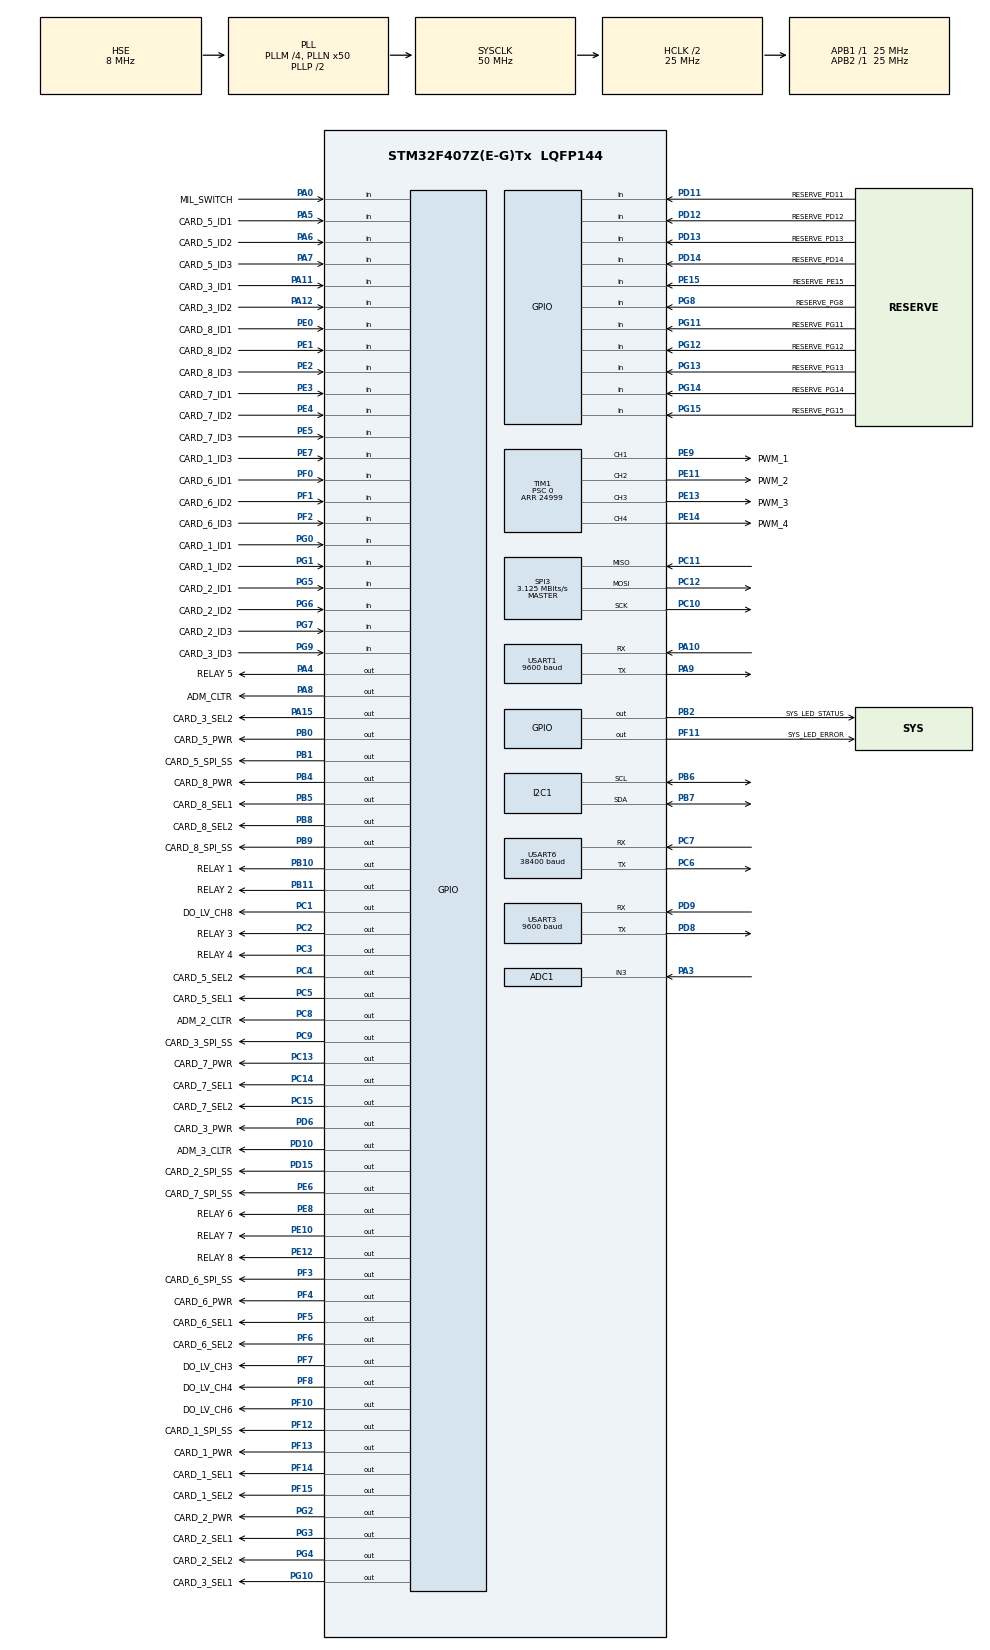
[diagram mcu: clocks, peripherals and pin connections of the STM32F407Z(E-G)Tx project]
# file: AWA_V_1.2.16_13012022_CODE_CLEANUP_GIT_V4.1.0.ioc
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ADC1.Channel-3\#ChannelRegularConversion=ADC_CHANNEL_3
ADC1.ContinuousConvMode=ENABLE
ADC1.EOCSelection=ADC_EOC_SEQ_CONV
ADC1.NbrOfConversion=1
ADC1.NbrOfConversionFlag=1
ADC1.Rank-3\#ChannelRegularConversion=1
ADC1.SamplingTime-3\#ChannelRegularConversion=ADC_SAMPLETIME_480CYCLES
ADC1.master=1
Dma.Request0=USART6_TX
Dma.USART6_TX.0.Direction=DMA_MEMORY_TO_PERIPH
Dma.USART6_TX.0.FIFOMode=DMA_FIFOMODE_DISABLE
Dma.USART6_TX.0.Instance=DMA2_Stream6
Dma.USART6_TX.0.MemDataAlignment=DMA_MDATAALIGN_BYTE
Dma.USART6_TX.0.MemInc=DMA_MINC_ENABLE
Dma.USART6_TX.0.Mode=DMA_NORMAL
Dma.USART6_TX.0.PeriphDataAlignment=DMA_PDATAALIGN_BYTE
Dma.USART6_TX.0.PeriphInc=DMA_PINC_DISABLE
Dma.USART6_TX.0.Priority=DMA_PRIORITY_VERY_HIGH
I2C1.I2C_Mode=I2C_Fast
Mcu.Family=STM32F4
Mcu.Name=STM32F407Z(E-G)Tx
Mcu.Package=LQFP144
NVIC.DMA2_Stream6_IRQn=true\:0\:0\:false\:false\:true\:true\:true
NVIC.PriorityGroup=NVIC_PRIORITYGROUP_4
NVIC.TIM2_IRQn=true\:0\:0\:false\:false\:true\:true\:true
NVIC.TIM3_IRQn=true\:0\:0\:true\:false\:true\:true\:true
NVIC.TIM4_IRQn=true\:0\:0\:false\:false\:true\:true\:true
NVIC.TIM5_IRQn=true\:0\:0\:false\:false\:true\:true\:true
NVIC.TIM6_DAC_IRQn=true\:0\:0\:false\:false\:true\:true\:true
NVIC.TIM7_IRQn=true\:0\:0\:false\:false\:true\:true\:true
NVIC.TIM8_BRK_TIM12_IRQn=true\:0\:0\:false\:false\:true\:true\:true
NVIC.USART1_IRQn=true\:0\:0\:false\:false\:true\:true\:true
NVIC.USART3_IRQn=true\:0\:0\:false\:false\:true\:true\:true
NVIC.USART6_IRQn=true\:0\:0\:false\:false\:true\:true\:true
PA0-WKUP.GPIO_Label=MIL_SWITCH
PA0-WKUP.Signal=GPIO_Input
PA10.Mode=Asynchronous
PA10.Signal=USART1_RX
PA11.GPIO_Label=CARD_3_ID1
PA11.Signal=GPIO_Input
PA12.GPIO_Label=CARD_3_ID2
PA12.Signal=GPIO_Input
PA13.Mode=Trace_Asynchronous_SW
PA13.Signal=SYS_JTMS-SWDIO
PA14.Mode=Trace_Asynchronous_SW
PA14.Signal=SYS_JTCK-SWCLK
PA15.GPIO_Label=CARD_3_SEL2
PA15.Signal=GPIO_Output
PA3.Signal=ADCx_IN3
PA4.GPIO_Label=RELAY 5
PA4.Signal=GPIO_Output
PA5.GPIO_Label=CARD_5_ID1
PA5.Signal=GPIO_Input
PA6.GPIO_Label=CARD_5_ID2
PA6.Signal=GPIO_Input
PA7.GPIO_Label=CARD_5_ID3
PA7.Signal=GPIO_Input
PA8.GPIO_Label=ADM_CLTR
PA8.Signal=GPIO_Output
PA9.Mode=Asynchronous
PA9.Signal=USART1_TX
PB0.GPIO_Label=CARD_5_PWR
PB0.Signal=GPIO_Output
PB1.GPIO_Label=CARD_5_SPI_SS
PB1.Signal=GPIO_Output
PB10.GPIO_Label=RELAY 1
PB10.Signal=GPIO_Output
PB11.GPIO_Label=RELAY 2
PB11.Signal=GPIO_Output
PB2.GPIO_Label=SYS_LED_STATUS
PB2.Signal=GPIO_Output
PB3.Mode=Trace_Asynchronous_SW
PB3.Signal=SYS_JTDO-SWO
PB4.GPIO_Label=CARD_8_PWR
PB4.Signal=GPIO_Output
PB5.GPIO_Label=CARD_8_SEL1
PB5.Signal=GPIO_Output
PB6.GPIO_PuPdOD=GPIO_NOPULL
PB6.Mode=I2C
PB6.Signal=I2C1_SCL
PB7.GPIO_PuPdOD=GPIO_NOPULL
PB7.Mode=I2C
PB7.Signal=I2C1_SDA
PB8.GPIO_Label=CARD_8_SEL2
PB8.Signal=GPIO_Output
PB9.GPIO_Label=CARD_8_SPI_SS
PB9.Signal=GPIO_Output
PC1.GPIO_Label=DO_LV_CH8
PC1.Signal=GPIO_Output
PC10.Mode=Full_Duplex_Master
PC10.Signal=SPI3_SCK
PC11.Mode=Full_Duplex_Master
PC11.Signal=SPI3_MISO
PC12.Mode=Full_Duplex_Master
PC12.Signal=SPI3_MOSI
PC13-ANTI_TAMP.GPIO_Label=CARD_7_PWR
PC13-ANTI_TAMP.Signal=GPIO_Output
PC14-OSC32_IN.GPIO_Label=CARD_7_SEL1
PC14-OSC32_IN.Signal=GPIO_Output
PC15-OSC32_OUT.GPIO_Label=CARD_7_SEL2
PC15-OSC32_OUT.Signal=GPIO_Output
PC2.GPIO_Label=RELAY 3
PC2.Signal=GPIO_Output
PC3.GPIO_Label=RELAY 4
PC3.Signal=GPIO_Output
PC4.GPIO_Label=CARD_5_SEL2
PC4.Signal=GPIO_Output
PC5.GPIO_Label=CARD_5_SEL1
PC5.Signal=GPIO_Output
PC6.Mode=Asynchronous
PC6.Signal=USART6_TX
PC7.Mode=Asynchronous
PC7.Signal=USART6_RX
PC8.GPIO_Label=ADM_2_CLTR
PC8.Signal=GPIO_Output
PC9.GPIO_Label=CARD_3_SPI_SS
PC9.Signal=GPIO_Output
PD10.GPIO_Label=ADM_3_CLTR
PD10.Signal=GPIO_Output
PD11.GPIO_Label=RESERVE_PD11
PD11.Signal=GPIO_Input
PD12.GPIO_Label=RESERVE_PD12
PD12.Signal=GPIO_Input
PD13.GPIO_Label=RESERVE_PD13
PD13.Signal=GPIO_Input
PD14.GPIO_Label=RESERVE_PD14
PD14.Signal=GPIO_Input
PD15.GPIO_Label=CARD_2_SPI_SS
PD15.Signal=GPIO_Output
PD6.GPIO_Label=CARD_3_PWR
PD6.Signal=GPIO_Output
PD8.Mode=Asynchronous
PD8.Signal=USART3_TX
PD9.Mode=Asynchronous
PD9.Signal=USART3_RX
PE0.GPIO_Label=CARD_8_ID1
PE0.Signal=GPIO_Input
PE1.GPIO_Label=CARD_8_ID2
PE1.Signal=GPIO_Input
PE10.GPIO_Label=RELAY 7
PE10.Signal=GPIO_Output
PE11.GPIO_Label=PWM_2
PE11.Signal=S_TIM1_CH2
PE12.GPIO_Label=RELAY 8
PE12.Signal=GPIO_Output
PE13.GPIO_Label=PWM_3
PE13.Signal=S_TIM1_CH3
PE14.GPIO_Label=PWM_4
PE14.Signal=S_TIM1_CH4
PE15.GPIO_Label=RESERVE_PE15
PE15.Signal=GPIO_Input
PE2.GPIO_Label=CARD_8_ID3
PE2.Signal=GPIO_Input
PE3.GPIO_Label=CARD_7_ID1
PE3.Signal=GPIO_Input
PE4.GPIO_Label=CARD_7_ID2
PE4.Signal=GPIO_Input
PE5.GPIO_Label=CARD_7_ID3
PE5.Signal=GPIO_Input
PE6.GPIO_Label=CARD_7_SPI_SS
PE6.Signal=GPIO_Output
PE7.GPIO_Label=CARD_1_ID3
PE7.Signal=GPIO_Input
PE8.GPIO_Label=RELAY 6
PE8.Signal=GPIO_Output
PE9.GPIO_Label=PWM_1
PE9.Signal=S_TIM1_CH1
PF0.GPIO_Label=CARD_6_ID1
PF0.Signal=GPIO_Input
PF1.GPIO_Label=CARD_6_ID2
PF1.Signal=GPIO_Input
PF10.GPIO_Label=DO_LV_CH6
PF10.Signal=GPIO_Output
PF11.GPIO_Label=SYS_LED_ERROR
PF11.Signal=GPIO_Output
PF12.GPIO_Label=CARD_1_SPI_SS
PF12.Signal=GPIO_Output
PF13.GPIO_Label=CARD_1_PWR
PF13.Signal=GPIO_Output
PF14.GPIO_Label=CARD_1_SEL1
PF14.Signal=GPIO_Output
PF15.GPIO_Label=CARD_1_SEL2
PF15.Signal=GPIO_Output
PF2.GPIO_Label=CARD_6_ID3
PF2.Signal=GPIO_Input
PF3.GPIO_Label=CARD_6_SPI_SS
PF3.Signal=GPIO_Output
PF4.GPIO_Label=CARD_6_PWR
PF4.Signal=GPIO_Output
PF5.GPIO_Label=CARD_6_SEL1
PF5.Signal=GPIO_Output
PF6.GPIO_Label=CARD_6_SEL2
PF6.Signal=GPIO_Output
PF7.GPIO_Label=DO_LV_CH3
PF7.Signal=GPIO_Output
PF8.GPIO_Label=DO_LV_CH4
PF8.Signal=GPIO_Output
PG0.GPIO_Label=CARD_1_ID1
PG0.Signal=GPIO_Input
PG1.GPIO_Label=CARD_1_ID2
PG1.Signal=GPIO_Input
PG10.GPIO_Label=CARD_3_SEL1
PG10.Signal=GPIO_Output
PG11.GPIO_Label=RESERVE_PG11
PG11.Signal=GPIO_Input
PG12.GPIO_Label=RESERVE_PG12
PG12.Signal=GPIO_Input
PG13.GPIO_Label=RESERVE_PG13
PG13.Signal=GPIO_Input
PG14.GPIO_Label=RESERVE_PG14
PG14.Signal=GPIO_Input
PG15.GPIO_Label=RESERVE_PG15
PG15.Signal=GPIO_Input
PG2.GPIO_Label=CARD_2_PWR
PG2.Signal=GPIO_Output
PG3.GPIO_Label=CARD_2_SEL1
PG3.Signal=GPIO_Output
PG4.GPIO_Label=CARD_2_SEL2
PG4.Signal=GPIO_Output
PG5.GPIO_Label=CARD_2_ID1
PG5.Signal=GPIO_Input
PG6.GPIO_Label=CARD_2_ID2
PG6.Signal=GPIO_Input
PG7.GPIO_Label=CARD_2_ID3
PG7.Signal=GPIO_Input
PG8.GPIO_Label=RESERVE_PG8
PG8.Signal=GPIO_Input
PG9.GPIO_Label=CARD_3_ID3
PG9.Signal=GPIO_Input
PH0-OSC_IN.Mode=HSE-External-Oscillator
PH0-OSC_IN.Signal=RCC_OSC_IN
PH1-OSC_OUT.Mode=HSE-External-Oscillator
PH1-OSC_OUT.Signal=RCC_OSC_OUT
ProjectManager.HeapSize=0x200
ProjectManager.StackSize=0x400
ProjectManager.TargetToolchain=STM32CubeIDE
RCC.48MHZClocksFreq_Value=25000000
RCC.AHBCLKDivider=RCC_SYSCLK_DIV2
RCC.AHBFreq_Value=25000000
RCC.APB1Freq_Value=25000000
RCC.APB1TimFreq_Value=25000000
RCC.APB2Freq_Value=25000000
RCC.APB2TimFreq_Value=25000000
RCC.CortexFreq_Value=25000000
RCC.HCLKFreq_Value=25000000
RCC.HSE_VALUE=8000000
RCC.HSI_VALUE=16000000
RCC.LSE_VALUE=32768
RCC.PLLM=4
RCC.PLLN=50
RCC.PLLSourceVirtual=RCC_PLLSOURCE_HSE
RCC.SYSCLKFreq_VALUE=50000000
RCC.SYSCLKSource=RCC_SYSCLKSOURCE_PLLCLK
RCC.VCOOutputFreq_Value=100000000
SH.ADCx_IN3.0=ADC1_IN3,IN3
SH.S_TIM1_CH1.0=TIM1_CH1,PWM Generation1 CH1
SH.S_TIM1_CH2.0=TIM1_CH2,PWM Generation2 CH2
SH.S_TIM1_CH3.0=TIM1_CH3,PWM Generation3 CH3
SH.S_TIM1_CH4.0=TIM1_CH4,PWM Generation4 CH4
SPI3.BaudRatePrescaler=SPI_BAUDRATEPRESCALER_8
SPI3.CalculateBaudRate=3.125 MBits/s
SPI3.DataSize=SPI_DATASIZE_16BIT
SPI3.Direction=SPI_DIRECTION_2LINES
SPI3.Mode=SPI_MODE_MASTER
SPI3.VirtualType=VM_MASTER
TIM1.AutoReloadPreload=TIM_AUTORELOAD_PRELOAD_DISABLE
TIM1.Channel-PWM\ Generation1\ CH1=TIM_CHANNEL_1
TIM1.Channel-PWM\ Generation2\ CH2=TIM_CHANNEL_2
TIM1.Channel-PWM\ Generation3\ CH3=TIM_CHANNEL_3
TIM1.Channel-PWM\ Generation4\ CH4=TIM_CHANNEL_4
TIM1.OCMode_PWM-PWM\ Generation1\ CH1=TIM_OCMODE_PWM2
TIM1.Period=24999
TIM1.Prescaler=0
TIM1.Pulse-PWM\ Generation1\ CH1=4000
TIM1.Pulse-PWM\ Generation2\ CH2=32
TIM1.Pulse-PWM\ Generation3\ CH3=32
TIM1.Pulse-PWM\ Generation4\ CH4=32
TIM12.Period=1
TIM12.Prescaler=2499
TIM2.AutoReloadPreload=TIM_AUTORELOAD_PRELOAD_ENABLE
TIM2.Period=99
TIM2.Prescaler=24
TIM3.Period=8
TIM3.Prescaler=24999
TIM4.Period=800
TIM4.Prescaler=25
TIM5.Period=1
TIM5.Prescaler=2499
TIM6.Period=999
TIM6.Prescaler=24999
TIM7.Period=1
TIM7.Prescaler=2499
USART1.BaudRate=9600
USART1.Parity=PARITY_NONE
USART1.StopBits=STOPBITS_1
USART1.VirtualMode=VM_ASYNC
USART3.BaudRate=9600
USART3.Parity=PARITY_NONE
USART3.VirtualMode=VM_ASYNC
USART6.BaudRate=38400
USART6.OverSampling=UART_OVERSAMPLING_8
USART6.Parity=PARITY_NONE
USART6.StopBits=STOPBITS_1
USART6.VirtualMode=VM_ASYNC
USART6.WordLength=WORDLENGTH_8B
VP_TIM12_VS_ClockSourceINT.Mode=Internal
VP_TIM1_VS_ClockSourceINT.Mode=Internal
VP_TIM2_VS_ClockSourceINT.Mode=Internal
VP_TIM3_VS_ClockSourceINT.Mode=Internal
VP_TIM4_VS_ClockSourceINT.Mode=Internal
VP_TIM5_VS_ClockSourceINT.Mode=Internal
VP_TIM6_VS_ClockSourceINT.Mode=Enable_Timer
VP_TIM7_VS_ClockSourceINT.Mode=Enable_Timer
board=custom

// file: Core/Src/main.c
/* USER CODE BEGIN Header */
/**
  ******************************************************************************
  * @file           : main.c
  * @brief          : Main program body
  ******************************************************************************
  * @attention
  *
  * <h2><center>&copy; Copyright (c) 2021 STMicroelectronics.
  * All rights reserved.</center></h2>
  *
  * This software component is licensed by ST under BSD 3-Clause license,
  * the "License"; You may not use this file except in compliance with the
  * License. You may obtain a copy of the License at:
  *                        opensource.org/licenses/BSD-3-Clause
  *
  ******************************************************************************
  */
/* USER CODE END Header */

#include "main.h"

/* USER CODE BEGIN Includes */
#include<stdlib.h>
#include<string.h>
#include "FM24CL64B.h"
#include "ADS1115.h"
#include "AD7682.h"
#include <math.h>
#include "stm32f4xx_dma.h"
#include "Application.h"
#include "Calibration.h"
#include "Initialization.h"
#include <time.h>

#define ITM_Port32(n)	(*((volatile unsigned long *)(0xe0000000 +4*n)))
#define SINGLE_SHOT 0
#define TEST	0
/* USER CODE END Includes */

ADC_HandleTypeDef hadc1;

I2C_HandleTypeDef hi2c1;

SPI_HandleTypeDef hspi3;

TIM_HandleTypeDef htim1;
TIM_HandleTypeDef htim2;
TIM_HandleTypeDef htim3;
TIM_HandleTypeDef htim4;
TIM_HandleTypeDef htim5;
TIM_HandleTypeDef htim6;
TIM_HandleTypeDef htim7;
TIM_HandleTypeDef htim12;

UART_HandleTypeDef huart1;
UART_HandleTypeDef huart3;
UART_HandleTypeDef huart6;
DMA_HandleTypeDef hdma_usart6_tx;

/* USER CODE BEGIN PV */
extern uint8_t uart_rx_buffer;			/*< Will receive single byte from UART and will transfer it to the RX buffer array.*/
extern uint8_t uart_rx_buffer_uart1;	/*< Will receive single byte from UART and will transfer it to the RX buffer array.*/
extern uint8_t uart_rx_buffer_uart3;	/*< Will receive single byte from UART and will transfer it to the RX buffer array.*/
/* USER CODE END PV */

void SystemClock_Config(void);
static void MX_GPIO_Init(void);
static void MX_TIM2_Init(void);
static void MX_TIM3_Init(void);
static void MX_TIM4_Init(void);
static void MX_I2C1_Init(void);
static void MX_SPI3_Init(void);
static void MX_TIM1_Init(void);
static void MX_USART3_UART_Init(void);
static void MX_TIM6_Init(void);
static void MX_USART1_UART_Init(void);
static void MX_USART6_UART_Init(void);
static void MX_ADC1_Init(void);
static void MX_DMA_Init(void);
static void MX_TIM7_Init(void);
static void MX_TIM5_Init(void);
static void MX_TIM12_Init(void);
/* USER CODE BEGIN PFP */

void ProcessCommandCommands(void);

void PWM_update(void);//test

float LinearEqCalc(float x, float x1, float x2, float y1, float y2);

/* USER CODE END PFP */

/* USER CODE BEGIN 0 */
uint8_t p[10];

uint16_t SlotCode[8];

int card_action = 0;
int calFlag = 0;

uint8_t cardScan = 1;
extern ADS1115_Config ADS1115_ReadConfigutationHandle_t;
typedef union{
	uint8_t bytes[2];
	uint16_t word;
}Data;
Data data_;

//AutoZero flag
uint8_t performAUTOZERO;
//Batch mode
uint8_t performBatchCycle;

int _write(int file, char *ptr, int len)
{
	int DataIdx;

	for (DataIdx = 0; DataIdx < len; DataIdx++)
	{
		//__io_putchar(*ptr++);
		ITM_SendChar(*ptr++);
	}
	return len;
}

static inline getconfig(void)
{
	data_.word = ADS1115_OperationReadConfiguration();
	ADS1115_ReadConfigutationHandle_t.ByteData[1] = data_.bytes[0];
	ADS1115_ReadConfigutationHandle_t.ByteData[0] = data_.bytes[1];
}
/* USER CODE END 0 */

int main(void)
{
  /* USER CODE BEGIN 1 */
  //Delay for other peripherals to initialise
//  HAL_Delay(20);
  //unsigned char SlotNo = 0;

  /* USER CODE END 1 */

  /* MCU Configuration--------------------------------------------------------*/

  /* Reset of all peripherals, Initializes the Flash interface and the Systick. */
  HAL_Init();

  /* Configure the system clock */
  SystemClock_Config();

  /* USER CODE BEGIN SysInit */
  ITM_Port32(31) = 1;
#if MODBUS_MULTI_DROP
  //HAL_UART_Receive_IT(&huart6, &uart_rx_buffer, 1);
#else
  //Configure DMA for UART 6 RX
  DMA_UART6_RX_Init();
#endif

  //Configure DMA for UART 1 RX
  //DMA_UART1_RX_Init();
#if QUERRY_RX_INIT_LEN_6
  DMA_UART1_RX_Init((uint32_t*)(&Rxbuff[0]),DMA_FIRST_TRANSACTION_NO); /*< Initialize the DMA2 Stream 5 with DMA_FIRST_TRANSACTION_NO*/
#else
  //DMA_UART1_RX_Init((uint32_t*)(&Rxbuff[0]),8); /*< Initialize the DMA2 Stream 5 with DMA_FIRST_TRANSACTION_NO*/
#endif
  /* USER CODE END SysInit */

  /* Initialize all configured peripherals */
  MX_GPIO_Init();
  MX_TIM2_Init();
  MX_TIM3_Init();
  MX_TIM4_Init();
  MX_I2C1_Init();
  MX_SPI3_Init();
  MX_TIM1_Init();
  MX_USART3_UART_Init();
  MX_TIM6_Init();
  MX_USART1_UART_Init();
  MX_USART6_UART_Init();
  MX_ADC1_Init();
  MX_DMA_Init();
  MX_TIM7_Init();
  MX_TIM5_Init();
  MX_TIM12_Init();
  /* USER CODE BEGIN 2 */
  ITM_Port32(31) = 2;

  //Enable the DMA 2 Stream for UART 6 RX
  //DMAPeripheralEnable(DMA2_Stream2, ENABLE);

  //Start the reception in UART6 using interrupt
  HAL_UART_Receive_IT(&huart6, &uart_rx_buffer, 1);

  //Enable the DMA 2 Stream for UART 1 RX
  //DMAPeripheralEnable(DMA2_Stream5, ENABLE);

  //Start the reception in UART6 using interrupt
  HAL_UART_Receive_IT(&huart1, &uart_rx_buffer_uart1, 1);

  //Start UART3 on interrupt
  HAL_UART_Receive_IT(&huart3, &uart_rx_buffer_uart3, 1);
  /* USER CODE END 2 */

  /* Infinite loop */
  /* USER CODE BEGIN WHILE */
  ADM_CLTR_LOW();

  ADM_2_CLTR_LOW();

  ADM_3_CLTR_LOW();
  //test
//  HoldingRegisterdefaultData();
  //FRAM_OperationWrite(FRAM_ADDRESS_CODSENSORLASTCALIB_HISTORY,(uint8_t*)&InputRegister_t.bytes[sizeof(PVhandle_t) + 328],204);
  //FRAM_OperationWrite(FRAM_ADDRESS_TSSSENSORLASTCALIB_HISTORY,(uint8_t*)&InputRegister_t.bytes[sizeof(PVhandle_t) + 532],204);
  //FRAM_OperationWrite(FRAM_ADDRESS_PHSENSLASTCALIB_HISTORY,(uint8_t*)&InputRegister_t.bytes[sizeof(PVhandle_t) + 532],204);
  //FRAM_OperationWrite(FRAM_ADDRESS_MIN,'\0',(1024*8)-1);
  ModbusReadConfiguration();
  HoldingRegisterdefaultData();
  startupMessages();
  /**************************/

  PWM_setup();
  HAL_TIM_PWM_Start(&htim1, TIM_CHANNEL_1);
  HAL_TIM_PWM_Start(&htim1, TIM_CHANNEL_2);
  HAL_TIM_PWM_Start(&htim1, TIM_CHANNEL_3);
  HAL_TIM_PWM_Start(&htim1, TIM_CHANNEL_4);

  HAL_GPIO_WritePin(SYS_LED_STATUS_GPIO_Port, SYS_LED_STATUS_Pin, GPIO_PIN_SET);
  HAL_GPIO_WritePin(SYS_LED_ERROR_GPIO_Port, SYS_LED_ERROR_Pin, GPIO_PIN_SET);

  //Read the ID in every SLOT
  ReadSlotID();

  //this is set to 0x01 when the start ADC command is received
  TimerStart = 0x02;
  //printf("Hello AWA!!!\n");
  //memset(&InputRegister_t.bytes[sizeof(PVhandle_t)],'\0',sizeof(InputRegister_t.bytes));
//  int flag_= 0;
  //FRAM_OperationWrite(FRAM_ADDRESS_LASTCALIB_HISTORY,(uint8_t*)&InputRegister_t.bytes[sizeof(PVhandle_t)],sizeof(InputRegister_t.bytes));
  //int size = sizeof(PVhandle_t) + sizeof(InputRegister_t.COD_lastCalibration);
#if TEST
  memset(&CurrentOutputCalibration_t,'\0',sizeof(CurrentOutputCalibration_t));
  FRAM_OperationWrite(FRAM_ADDRESS_AO_ELEC_CALIB, (uint8_t*)&CurrentOutputCalibration_t, sizeof(CurrentOutputCalibration_t));
#endif
  //float arrayADC [1000];
  uint16_t samples = 100;
  //float avgs = (float)samples;

  /*Start the internal ADC*/
  InternalADCStartConversion();

  //Initiate the queue
  initqueue();

  float Current_COD_SF = 0;
  float Current_TSS_SF = 0;
  float Current_COD_C[4];
  float Current_TSS_C[3];
  float Current_CheckScreen_sample_on_time = 0;
  float Current_CheckScreen_sample_wait_time = 0;
  float Current_CheckScreen_clean_on_time = 0;
  float Current_CheckScreen_clean_wait_time = 0;
  float Current_CheckScreen_No_of_flashes = 0;

  Current_COD_SF = HoldingRegister_t.ModeCommand_t.COD_SF;
  Current_TSS_SF = HoldingRegister_t.ModeCommand_t.TSS_SF;
  //memcpy(HoldingRegister_t.ModeCommand_t.C,Current_COD_C,sizeof(Current_COD_C));//Source,dest,size
  //memcpy(HoldingRegister_t.ModeCommand_t.TSS_K,Current_TSS_C,sizeof(Current_TSS_C));
  Current_CheckScreen_sample_on_time = HoldingRegister_t.ModeCommand_t.CS_PUMP1_ONTIME;
  Current_CheckScreen_sample_wait_time = HoldingRegister_t.ModeCommand_t.CS_PUMP1_DELAY;
  Current_CheckScreen_clean_on_time = HoldingRegister_t.ModeCommand_t.CS_PUMP2_ONTIME;
  Current_CheckScreen_clean_wait_time = HoldingRegister_t.ModeCommand_t.CS_PUMP2_DELAY;
  Current_CheckScreen_No_of_flashes = HoldingRegister_t.ModeCommand_t.CS_FLASH;

  while (1)
  {

	  //Process the commands from the HMI
	  ProcessModesCommands();

	  //Relay outputs and analog outputs
	  Application_AWAIOProcess();

    /* USER CODE END WHILE */

    /* USER CODE BEGIN 3 */

	  //Parses the data received from the MODBUS master and execute the command received
	  Application_MODBUSParseQuery();

	  //Stores the process variables and calibration data if the respective flag is raised
	  Application_StoreData();

	  /*COD process controls*/
	  FlowSensorReadStatus();
	  MILSwitchReadStatus();

	  //Send the data to RTU
	  setRTUData();

	  //Check for data change
	  if(Current_COD_SF != HoldingRegister_t.ModeCommand_t.COD_SF ||
			Current_TSS_SF != HoldingRegister_t.ModeCommand_t.TSS_SF ||
			Current_CheckScreen_sample_on_time != HoldingRegister_t.ModeCommand_t.CS_PUMP1_ONTIME||
			Current_CheckScreen_sample_wait_time != HoldingRegister_t.ModeCommand_t.CS_PUMP1_DELAY||
			Current_CheckScreen_clean_on_time != HoldingRegister_t.ModeCommand_t.CS_PUMP2_ONTIME||
			Current_CheckScreen_clean_wait_time != HoldingRegister_t.ModeCommand_t.CS_PUMP2_DELAY||
			Current_CheckScreen_No_of_flashes != HoldingRegister_t.ModeCommand_t.CS_FLASH)
	  {
		  Current_COD_SF = HoldingRegister_t.ModeCommand_t.COD_SF;
		  COD_10ptFactoryCalibrationHandle_t.SF = Current_COD_SF;

		  Current_TSS_SF = HoldingRegister_t.ModeCommand_t.TSS_SF;
		  TSS_10ptFactoryCalibrationHandle_t.SF = Current_TSS_SF;

		  Current_CheckScreen_sample_on_time = HoldingRegister_t.ModeCommand_t.CS_PUMP1_ONTIME;
		  Current_CheckScreen_sample_wait_time = HoldingRegister_t.ModeCommand_t.CS_PUMP1_DELAY;
		  Current_CheckScreen_clean_on_time = HoldingRegister_t.ModeCommand_t.CS_PUMP2_ONTIME;
		  Current_CheckScreen_clean_wait_time = HoldingRegister_t.ModeCommand_t.CS_PUMP2_DELAY;

		  Current_CheckScreen_No_of_flashes = HoldingRegister_t.ModeCommand_t.CS_FLASH;

		  FRAM_OperationWrite(FRAM_ADDRESS_MIN, (uint8_t*)&HoldingRegister_t.bytes, sizeof(HoldingRegister_t.bytes));
	  }
  }
  /* USER CODE END 3 */
}

void SystemClock_Config(void)
{
  RCC_OscInitTypeDef RCC_OscInitStruct = {0};
  RCC_ClkInitTypeDef RCC_ClkInitStruct = {0};

  /** Configure the main internal regulator output voltage
  */
  __HAL_RCC_PWR_CLK_ENABLE();
  __HAL_PWR_VOLTAGESCALING_CONFIG(PWR_REGULATOR_VOLTAGE_SCALE1);
  /** Initializes the CPU, AHB and APB busses clocks
  */
  RCC_OscInitStruct.OscillatorType = RCC_OSCILLATORTYPE_HSE;
  RCC_OscInitStruct.HSEState = RCC_HSE_ON;
  RCC_OscInitStruct.PLL.PLLState = RCC_PLL_ON;
  RCC_OscInitStruct.PLL.PLLSource = RCC_PLLSOURCE_HSE;
  RCC_OscInitStruct.PLL.PLLM = 4;
  RCC_OscInitStruct.PLL.PLLN = 50;
  RCC_OscInitStruct.PLL.PLLP = RCC_PLLP_DIV2;
  RCC_OscInitStruct.PLL.PLLQ = 4;
  if (HAL_RCC_OscConfig(&RCC_OscInitStruct) != HAL_OK)
  {
    Error_Handler();
  }
  /** Initializes the CPU, AHB and APB busses clocks
  */
  RCC_ClkInitStruct.ClockType = RCC_CLOCKTYPE_HCLK|RCC_CLOCKTYPE_SYSCLK
                              |RCC_CLOCKTYPE_PCLK1|RCC_CLOCKTYPE_PCLK2;
  RCC_ClkInitStruct.SYSCLKSource = RCC_SYSCLKSOURCE_PLLCLK;
  RCC_ClkInitStruct.AHBCLKDivider = RCC_SYSCLK_DIV2;
  RCC_ClkInitStruct.APB1CLKDivider = RCC_HCLK_DIV1;
  RCC_ClkInitStruct.APB2CLKDivider = RCC_HCLK_DIV1;

  if (HAL_RCC_ClockConfig(&RCC_ClkInitStruct, FLASH_LATENCY_0) != HAL_OK)
  {
    Error_Handler();
  }
}

static void MX_ADC1_Init(void)
{

  ADC_ChannelConfTypeDef sConfig = {0};

  /** Configure the global features of the ADC (Clock, Resolution, Data Alignment and number of conversion)
  */
  hadc1.Instance = ADC1;
  hadc1.Init.ClockPrescaler = ADC_CLOCK_SYNC_PCLK_DIV2;
  hadc1.Init.Resolution = ADC_RESOLUTION_12B;
  hadc1.Init.ScanConvMode = DISABLE;
  hadc1.Init.ContinuousConvMode = ENABLE;
  hadc1.Init.DiscontinuousConvMode = DISABLE;
  hadc1.Init.ExternalTrigConvEdge = ADC_EXTERNALTRIGCONVEDGE_NONE;
  hadc1.Init.ExternalTrigConv = ADC_SOFTWARE_START;
  hadc1.Init.DataAlign = ADC_DATAALIGN_RIGHT;
  hadc1.Init.NbrOfConversion = 1;
  hadc1.Init.DMAContinuousRequests = DISABLE;
  hadc1.Init.EOCSelection = ADC_EOC_SEQ_CONV;
  if (HAL_ADC_Init(&hadc1) != HAL_OK)
  {
    Error_Handler();
  }
  /** Configure for the selected ADC regular channel its corresponding rank in the sequencer and its sample time.
  */
  sConfig.Channel = ADC_CHANNEL_3;
  sConfig.Rank = 1;
  sConfig.SamplingTime = ADC_SAMPLETIME_480CYCLES;
  if (HAL_ADC_ConfigChannel(&hadc1, &sConfig) != HAL_OK)
  {
    Error_Handler();
  }

}

static void MX_I2C1_Init(void)
{

  hi2c1.Instance = I2C1;
  hi2c1.Init.ClockSpeed = 400000;
  hi2c1.Init.DutyCycle = I2C_DUTYCYCLE_2;
  hi2c1.Init.OwnAddress1 = 0;
  hi2c1.Init.AddressingMode = I2C_ADDRESSINGMODE_7BIT;
  hi2c1.Init.DualAddressMode = I2C_DUALADDRESS_DISABLE;
  hi2c1.Init.OwnAddress2 = 0;
  hi2c1.Init.GeneralCallMode = I2C_GENERALCALL_DISABLE;
  hi2c1.Init.NoStretchMode = I2C_NOSTRETCH_DISABLE;
  if (HAL_I2C_Init(&hi2c1) != HAL_OK)
  {
    Error_Handler();
  }

}

static void MX_SPI3_Init(void)
{

  /* SPI3 parameter configuration*/
  hspi3.Instance = SPI3;
  hspi3.Init.Mode = SPI_MODE_MASTER;
  hspi3.Init.Direction = SPI_DIRECTION_2LINES;
  hspi3.Init.DataSize = SPI_DATASIZE_16BIT;
  hspi3.Init.CLKPolarity = SPI_POLARITY_LOW;
  hspi3.Init.CLKPhase = SPI_PHASE_1EDGE;
  hspi3.Init.NSS = SPI_NSS_SOFT;
  hspi3.Init.BaudRatePrescaler = SPI_BAUDRATEPRESCALER_8;
  hspi3.Init.FirstBit = SPI_FIRSTBIT_MSB;
  hspi3.Init.TIMode = SPI_TIMODE_DISABLE;
  hspi3.Init.CRCCalculation = SPI_CRCCALCULATION_DISABLE;
  hspi3.Init.CRCPolynomial = 10;
  if (HAL_SPI_Init(&hspi3) != HAL_OK)
  {
    Error_Handler();
  }

}

static void MX_TIM1_Init(void)
{

  TIM_ClockConfigTypeDef sClockSourceConfig = {0};
  TIM_MasterConfigTypeDef sMasterConfig = {0};
  TIM_OC_InitTypeDef sConfigOC = {0};
  TIM_BreakDeadTimeConfigTypeDef sBreakDeadTimeConfig = {0};

  htim1.Instance = TIM1;
  htim1.Init.Prescaler = 0;
  htim1.Init.CounterMode = TIM_COUNTERMODE_UP;
  htim1.Init.Period = 24999;
  htim1.Init.ClockDivision = TIM_CLOCKDIVISION_DIV1;
  htim1.Init.RepetitionCounter = 0;
  htim1.Init.AutoReloadPreload = TIM_AUTORELOAD_PRELOAD_DISABLE;
  if (HAL_TIM_Base_Init(&htim1) != HAL_OK)
  {
    Error_Handler();
  }
  sClockSourceConfig.ClockSource = TIM_CLOCKSOURCE_INTERNAL;
  if (HAL_TIM_ConfigClockSource(&htim1, &sClockSourceConfig) != HAL_OK)
  {
    Error_Handler();
  }
  if (HAL_TIM_PWM_Init(&htim1) != HAL_OK)
  {
    Error_Handler();
  }
  sMasterConfig.MasterOutputTrigger = TIM_TRGO_RESET;
  sMasterConfig.MasterSlaveMode = TIM_MASTERSLAVEMODE_DISABLE;
  if (HAL_TIMEx_MasterConfigSynchronization(&htim1, &sMasterConfig) != HAL_OK)
  {
    Error_Handler();
  }
  sConfigOC.OCMode = TIM_OCMODE_PWM2;
  sConfigOC.Pulse = 4000;
  sConfigOC.OCPolarity = TIM_OCPOLARITY_HIGH;
  sConfigOC.OCNPolarity = TIM_OCNPOLARITY_HIGH;
  sConfigOC.OCFastMode = TIM_OCFAST_DISABLE;
  sConfigOC.OCIdleState = TIM_OCIDLESTATE_RESET;
  sConfigOC.OCNIdleState = TIM_OCNIDLESTATE_RESET;
  if (HAL_TIM_PWM_ConfigChannel(&htim1, &sConfigOC, TIM_CHANNEL_1) != HAL_OK)
  {
    Error_Handler();
  }
  sConfigOC.OCMode = TIM_OCMODE_PWM1;
  sConfigOC.Pulse = 32;
  if (HAL_TIM_PWM_ConfigChannel(&htim1, &sConfigOC, TIM_CHANNEL_2) != HAL_OK)
  {
    Error_Handler();
  }
  if (HAL_TIM_PWM_ConfigChannel(&htim1, &sConfigOC, TIM_CHANNEL_3) != HAL_OK)
  {
    Error_Handler();
  }
  if (HAL_TIM_PWM_ConfigChannel(&htim1, &sConfigOC, TIM_CHANNEL_4) != HAL_OK)
  {
    Error_Handler();
  }
  sBreakDeadTimeConfig.OffStateRunMode = TIM_OSSR_DISABLE;
  sBreakDeadTimeConfig.OffStateIDLEMode = TIM_OSSI_DISABLE;
  sBreakDeadTimeConfig.LockLevel = TIM_LOCKLEVEL_OFF;
  sBreakDeadTimeConfig.DeadTime = 0;
  sBreakDeadTimeConfig.BreakState = TIM_BREAK_DISABLE;
  sBreakDeadTimeConfig.BreakPolarity = TIM_BREAKPOLARITY_HIGH;
  sBreakDeadTimeConfig.AutomaticOutput = TIM_AUTOMATICOUTPUT_DISABLE;
  if (HAL_TIMEx_ConfigBreakDeadTime(&htim1, &sBreakDeadTimeConfig) != HAL_OK)
  {
    Error_Handler();
  }
  HAL_TIM_MspPostInit(&htim1);

}

static void MX_TIM2_Init(void)
{

  TIM_ClockConfigTypeDef sClockSourceConfig = {0};
  TIM_MasterConfigTypeDef sMasterConfig = {0};

  htim2.Instance = TIM2;
  htim2.Init.Prescaler = 24;
  htim2.Init.CounterMode = TIM_COUNTERMODE_UP;
  htim2.Init.Period = 99;
  htim2.Init.ClockDivision = TIM_CLOCKDIVISION_DIV1;
  htim2.Init.AutoReloadPreload = TIM_AUTORELOAD_PRELOAD_ENABLE;
  if (HAL_TIM_Base_Init(&htim2) != HAL_OK)
  {
    Error_Handler();
  }
  sClockSourceConfig.ClockSource = TIM_CLOCKSOURCE_INTERNAL;
  if (HAL_TIM_ConfigClockSource(&htim2, &sClockSourceConfig) != HAL_OK)
  {
    Error_Handler();
  }
  sMasterConfig.MasterOutputTrigger = TIM_TRGO_RESET;
  sMasterConfig.MasterSlaveMode = TIM_MASTERSLAVEMODE_DISABLE;
  if (HAL_TIMEx_MasterConfigSynchronization(&htim2, &sMasterConfig) != HAL_OK)
  {
    Error_Handler();
  }
  /* USER CODE BEGIN TIM2_Init 2 */
  htim2.Instance->SR = 0;
  /* USER CODE END TIM2_Init 2 */

}

static void MX_TIM3_Init(void)
{

  TIM_ClockConfigTypeDef sClockSourceConfig = {0};
  TIM_MasterConfigTypeDef sMasterConfig = {0};

  htim3.Instance = TIM3;
  htim3.Init.Prescaler = 24999;
  htim3.Init.CounterMode = TIM_COUNTERMODE_UP;
  htim3.Init.Period = 8;
  htim3.Init.ClockDivision = TIM_CLOCKDIVISION_DIV1;
  htim3.Init.AutoReloadPreload = TIM_AUTORELOAD_PRELOAD_DISABLE;
  if (HAL_TIM_Base_Init(&htim3) != HAL_OK)
  {
    Error_Handler();
  }
  sClockSourceConfig.ClockSource = TIM_CLOCKSOURCE_INTERNAL;
  if (HAL_TIM_ConfigClockSource(&htim3, &sClockSourceConfig) != HAL_OK)
  {
    Error_Handler();
  }
  sMasterConfig.MasterOutputTrigger = TIM_TRGO_RESET;
  sMasterConfig.MasterSlaveMode = TIM_MASTERSLAVEMODE_DISABLE;
  if (HAL_TIMEx_MasterConfigSynchronization(&htim3, &sMasterConfig) != HAL_OK)
  {
    Error_Handler();
  }
  /* USER CODE BEGIN TIM3_Init 2 */
  htim3.Instance->SR = 0;
  /* USER CODE END TIM3_Init 2 */

}

static void MX_TIM4_Init(void)
{

  TIM_ClockConfigTypeDef sClockSourceConfig = {0};
  TIM_MasterConfigTypeDef sMasterConfig = {0};

  htim4.Instance = TIM4;
  htim4.Init.Prescaler = 25;
  htim4.Init.CounterMode = TIM_COUNTERMODE_UP;
  htim4.Init.Period = 800;
  htim4.Init.ClockDivision = TIM_CLOCKDIVISION_DIV1;
  htim4.Init.AutoReloadPreload = TIM_AUTORELOAD_PRELOAD_DISABLE;
  if (HAL_TIM_Base_Init(&htim4) != HAL_OK)
  {
    Error_Handler();
  }
  sClockSourceConfig.ClockSource = TIM_CLOCKSOURCE_INTERNAL;
  if (HAL_TIM_ConfigClockSource(&htim4, &sClockSourceConfig) != HAL_OK)
  {
    Error_Handler();
  }
  sMasterConfig.MasterOutputTrigger = TIM_TRGO_RESET;
  sMasterConfig.MasterSlaveMode = TIM_MASTERSLAVEMODE_DISABLE;
  if (HAL_TIMEx_MasterConfigSynchronization(&htim4, &sMasterConfig) != HAL_OK)
  {
    Error_Handler();
  }
  /* USER CODE BEGIN TIM4_Init 2 */
  htim4.Instance->SR = 0;
  /* USER CODE END TIM4_Init 2 */

}

static void MX_TIM5_Init(void)
{

  TIM_ClockConfigTypeDef sClockSourceConfig = {0};
  TIM_MasterConfigTypeDef sMasterConfig = {0};

  htim5.Instance = TIM5;
  htim5.Init.Prescaler = 2499;
  htim5.Init.CounterMode = TIM_COUNTERMODE_UP;
  htim5.Init.Period = 1;
  htim5.Init.ClockDivision = TIM_CLOCKDIVISION_DIV1;
  htim5.Init.AutoReloadPreload = TIM_AUTORELOAD_PRELOAD_DISABLE;
  if (HAL_TIM_Base_Init(&htim5) != HAL_OK)
  {
    Error_Handler();
  }
  sClockSourceConfig.ClockSource = TIM_CLOCKSOURCE_INTERNAL;
  if (HAL_TIM_ConfigClockSource(&htim5, &sClockSourceConfig) != HAL_OK)
  {
    Error_Handler();
  }
  sMasterConfig.MasterOutputTrigger = TIM_TRGO_RESET;
  sMasterConfig.MasterSlaveMode = TIM_MASTERSLAVEMODE_DISABLE;
  if (HAL_TIMEx_MasterConfigSynchronization(&htim5, &sMasterConfig) != HAL_OK)
  {
    Error_Handler();
  }

}

static void MX_TIM6_Init(void)
{

  TIM_MasterConfigTypeDef sMasterConfig = {0};

  htim6.Instance = TIM6;
  htim6.Init.Prescaler = 24999;
  htim6.Init.CounterMode = TIM_COUNTERMODE_UP;
  htim6.Init.Period = 999;
  htim6.Init.AutoReloadPreload = TIM_AUTORELOAD_PRELOAD_DISABLE;
  if (HAL_TIM_Base_Init(&htim6) != HAL_OK)
  {
    Error_Handler();
  }
  sMasterConfig.MasterOutputTrigger = TIM_TRGO_RESET;
  sMasterConfig.MasterSlaveMode = TIM_MASTERSLAVEMODE_DISABLE;
  if (HAL_TIMEx_MasterConfigSynchronization(&htim6, &sMasterConfig) != HAL_OK)
  {
    Error_Handler();
  }
  /* USER CODE BEGIN TIM6_Init 2 */
	htim6.Instance->SR = 0; // clear interrupt flag
	htim6.Instance->DIER &= ~TIM_IT_UPDATE; //DISnable timer interrupt flag
	htim6.Instance->CR1 &= ~TIM_CR1_CEN; // disable timer
  /* USER CODE END TIM6_Init 2 */

}

static void MX_TIM7_Init(void)
{

  TIM_MasterConfigTypeDef sMasterConfig = {0};

  htim7.Instance = TIM7;
  htim7.Init.Prescaler = 2499;
  htim7.Init.CounterMode = TIM_COUNTERMODE_UP;
  htim7.Init.Period = 1;
  htim7.Init.AutoReloadPreload = TIM_AUTORELOAD_PRELOAD_DISABLE;
  if (HAL_TIM_Base_Init(&htim7) != HAL_OK)
  {
    Error_Handler();
  }
  sMasterConfig.MasterOutputTrigger = TIM_TRGO_RESET;
  sMasterConfig.MasterSlaveMode = TIM_MASTERSLAVEMODE_DISABLE;
  if (HAL_TIMEx_MasterConfigSynchronization(&htim7, &sMasterConfig) != HAL_OK)
  {
    Error_Handler();
  }
  /* USER CODE BEGIN TIM7_Init 2 */

  /*Start the timer in interrupt mode*/
  //HAL_TIM_Base_Start_IT(&htim7);
  /* USER CODE END TIM7_Init 2 */

}

static void MX_TIM12_Init(void)
{

  TIM_ClockConfigTypeDef sClockSourceConfig = {0};

  htim12.Instance = TIM12;
  htim12.Init.Prescaler = 2499;
  htim12.Init.CounterMode = TIM_COUNTERMODE_UP;
  htim12.Init.Period = 1;
  htim12.Init.ClockDivision = TIM_CLOCKDIVISION_DIV1;
  htim12.Init.AutoReloadPreload = TIM_AUTORELOAD_PRELOAD_DISABLE;
  if (HAL_TIM_Base_Init(&htim12) != HAL_OK)
  {
    Error_Handler();
  }
  sClockSourceConfig.ClockSource = TIM_CLOCKSOURCE_INTERNAL;
  if (HAL_TIM_ConfigClockSource(&htim12, &sClockSourceConfig) != HAL_OK)
  {
    Error_Handler();
  }

}

static void MX_USART1_UART_Init(void)
{

  huart1.Instance = USART1;
  huart1.Init.BaudRate = 9600;
  huart1.Init.WordLength = UART_WORDLENGTH_8B;
  huart1.Init.StopBits = UART_STOPBITS_1;
  huart1.Init.Parity = UART_PARITY_NONE;
  huart1.Init.Mode = UART_MODE_TX_RX;
  huart1.Init.HwFlowCtl = UART_HWCONTROL_NONE;
  huart1.Init.OverSampling = UART_OVERSAMPLING_16;
  if (HAL_UART_Init(&huart1) != HAL_OK)
  {
    Error_Handler();
  }
  /* USER CODE BEGIN USART1_Init 2 */
  //huart1.Instance->CR1 |= UART_IT_RXNE; // UART RX not empty interrupt enable
  huart1.Instance->SR &= !USART_SR_TC;
  huart1.Instance->CR3 |= USART_CR3_DMAR;
  /* USER CODE END USART1_Init 2 */

}

static void MX_USART3_UART_Init(void)
{

  huart3.Instance = USART3;
  huart3.Init.BaudRate = 9600;
  huart3.Init.WordLength = UART_WORDLENGTH_8B;
  huart3.Init.StopBits = UART_STOPBITS_1;
  huart3.Init.Parity = UART_PARITY_NONE;
  huart3.Init.Mode = UART_MODE_TX_RX;
  huart3.Init.HwFlowCtl = UART_HWCONTROL_NONE;
  huart3.Init.OverSampling = UART_OVERSAMPLING_16;
  if (HAL_UART_Init(&huart3) != HAL_OK)
  {
    Error_Handler();
  }
  /* USER CODE BEGIN USART3_Init 2 */
  huart3.Instance->CR1 |= UART_IT_RXNE; // UART RX not empty interrupt enable
  /* USER CODE END USART3_Init 2 */

}

static void MX_USART6_UART_Init(void)
{

  huart6.Instance = USART6;
  huart6.Init.BaudRate = 38400;
  huart6.Init.WordLength = UART_WORDLENGTH_8B;
  huart6.Init.StopBits = UART_STOPBITS_1;
  huart6.Init.Parity = UART_PARITY_NONE;
  huart6.Init.Mode = UART_MODE_TX_RX;
  huart6.Init.HwFlowCtl = UART_HWCONTROL_NONE;
  huart6.Init.OverSampling = UART_OVERSAMPLING_8;
  if (HAL_UART_Init(&huart6) != HAL_OK)
  {
    Error_Handler();
  }
  /* USER CODE BEGIN USART6_Init 2 */
  //huart6.Instance->CR1 |= UART_IT_RXNE; // UART RX not empty interrupt enable
  //Enable DMA receive
  huart6.Instance->SR &= !USART_SR_TC;
  //huart6.Instance->CR3 |= USART_CR3_DMAR;
  /* USER CODE END USART6_Init 2 */

}

static void MX_DMA_Init(void)
{

  /* DMA controller clock enable */
  __HAL_RCC_DMA2_CLK_ENABLE();

  /* DMA interrupt init */
  /* DMA2_Stream6_IRQn interrupt configuration */
  HAL_NVIC_SetPriority(DMA2_Stream6_IRQn, 0, 0);
  HAL_NVIC_EnableIRQ(DMA2_Stream6_IRQn);

}

static void MX_GPIO_Init(void)
{
  GPIO_InitTypeDef GPIO_InitStruct = {0};

  /* GPIO Ports Clock Enable */
  __HAL_RCC_GPIOE_CLK_ENABLE();
  __HAL_RCC_GPIOC_CLK_ENABLE();
  __HAL_RCC_GPIOF_CLK_ENABLE();
  __HAL_RCC_GPIOH_CLK_ENABLE();
  __HAL_RCC_GPIOA_CLK_ENABLE();
  __HAL_RCC_GPIOB_CLK_ENABLE();
  __HAL_RCC_GPIOG_CLK_ENABLE();
  __HAL_RCC_GPIOD_CLK_ENABLE();

  /*Configure GPIO pin Output Level */
  HAL_GPIO_WritePin(GPIOE, CARD_7_SPI_SS_Pin|RELAY_6_Pin|RELAY_7_Pin|RELAY_8_Pin, GPIO_PIN_RESET);

  /*Configure GPIO pin Output Level */
  HAL_GPIO_WritePin(GPIOC, CARD_7_PWR_Pin|CARD_7_SEL1_Pin|CARD_7_SEL2_Pin|DO_LV_CH8_Pin
                          |RELAY_3_Pin|RELAY_4_Pin|CARD_5_SEL2_Pin|CARD_5_SEL1_Pin
                          |ADM_2_CLTR_Pin|CARD_3_SPI_SS_Pin, GPIO_PIN_RESET);

  /*Configure GPIO pin Output Level */
  HAL_GPIO_WritePin(GPIOF, CARD_6_SPI_SS_Pin|CARD_6_PWR_Pin|CARD_6_SEL1_Pin|CARD_6_SEL2_Pin
                          |DO_LV_CH3_Pin|DO_LV_CH4_Pin|DO_LV_CH6_Pin|SYS_LED_ERROR_Pin
                          |CARD_1_SPI_SS_Pin|CARD_1_PWR_Pin|CARD_1_SEL1_Pin|CARD_1_SEL2_Pin, GPIO_PIN_RESET);

  /*Configure GPIO pin Output Level */
  HAL_GPIO_WritePin(GPIOA, RELAY_5_Pin|ADM_CLTR_Pin|CARD_3_SEL2_Pin, GPIO_PIN_RESET);

  /*Configure GPIO pin Output Level */
  HAL_GPIO_WritePin(GPIOB, CARD_5_PWR_Pin|CARD_5_SPI_SS_Pin|SYS_LED_STATUS_Pin|RELAY_1_Pin
                          |RELAY_2_Pin|CARD_8_PWR_Pin|CARD_8_SEL1_Pin|CARD_8_SEL2_Pin
                          |CARD_8_SPI_SS_Pin, GPIO_PIN_RESET);

  /*Configure GPIO pin Output Level */
  HAL_GPIO_WritePin(GPIOD, ADM_3_CLTR_Pin|CARD_2_SPI_SS_Pin|CARD_3_PWR_Pin, GPIO_PIN_RESET);

  /*Configure GPIO pin Output Level */
  HAL_GPIO_WritePin(GPIOG, CARD_2_PWR_Pin|CARD_2_SEL1_Pin|CARD_2_SEL2_Pin|CARD_3_SEL1_Pin, GPIO_PIN_RESET);

  /*Configure GPIO pins : CARD_8_ID3_Pin CARD_7_ID1_Pin CARD_7_ID2_Pin CARD_7_ID3_Pin
                           CARD_1_ID3_Pin RESERVE_PE15_Pin CARD_8_ID1_Pin CARD_8_ID2_Pin */
  GPIO_InitStruct.Pin = CARD_8_ID3_Pin|CARD_7_ID1_Pin|CARD_7_ID2_Pin|CARD_7_ID3_Pin
                          |CARD_1_ID3_Pin|RESERVE_PE15_Pin|CARD_8_ID1_Pin|CARD_8_ID2_Pin;
  GPIO_InitStruct.Mode = GPIO_MODE_INPUT;
  GPIO_InitStruct.Pull = GPIO_NOPULL;
  HAL_GPIO_Init(GPIOE, &GPIO_InitStruct);

  /*Configure GPIO pins : CARD_7_SPI_SS_Pin RELAY_6_Pin RELAY_7_Pin RELAY_8_Pin */
  GPIO_InitStruct.Pin = CARD_7_SPI_SS_Pin|RELAY_6_Pin|RELAY_7_Pin|RELAY_8_Pin;
  GPIO_InitStruct.Mode = GPIO_MODE_OUTPUT_PP;
  GPIO_InitStruct.Pull = GPIO_NOPULL;
  GPIO_InitStruct.Speed = GPIO_SPEED_FREQ_LOW;
  HAL_GPIO_Init(GPIOE, &GPIO_InitStruct);

  /*Configure GPIO pins : CARD_7_PWR_Pin CARD_7_SEL1_Pin CARD_7_SEL2_Pin DO_LV_CH8_Pin
                           RELAY_3_Pin RELAY_4_Pin CARD_5_SEL2_Pin CARD_5_SEL1_Pin
                           ADM_2_CLTR_Pin CARD_3_SPI_SS_Pin */
  GPIO_InitStruct.Pin = CARD_7_PWR_Pin|CARD_7_SEL1_Pin|CARD_7_SEL2_Pin|DO_LV_CH8_Pin
                          |RELAY_3_Pin|RELAY_4_Pin|CARD_5_SEL2_Pin|CARD_5_SEL1_Pin
                          |ADM_2_CLTR_Pin|CARD_3_SPI_SS_Pin;
  GPIO_InitStruct.Mode = GPIO_MODE_OUTPUT_PP;
  GPIO_InitStruct.Pull = GPIO_NOPULL;
  GPIO_InitStruct.Speed = GPIO_SPEED_FREQ_LOW;
  HAL_GPIO_Init(GPIOC, &GPIO_InitStruct);

  /*Configure GPIO pins : CARD_6_ID1_Pin CARD_6_ID2_Pin CARD_6_ID3_Pin */
  GPIO_InitStruct.Pin = CARD_6_ID1_Pin|CARD_6_ID2_Pin|CARD_6_ID3_Pin;
  GPIO_InitStruct.Mode = GPIO_MODE_INPUT;
  GPIO_InitStruct.Pull = GPIO_NOPULL;
  HAL_GPIO_Init(GPIOF, &GPIO_InitStruct);

  /*Configure GPIO pins : CARD_6_SPI_SS_Pin CARD_6_PWR_Pin CARD_6_SEL1_Pin CARD_6_SEL2_Pin
                           DO_LV_CH3_Pin DO_LV_CH4_Pin DO_LV_CH6_Pin SYS_LED_ERROR_Pin
                           CARD_1_SPI_SS_Pin CARD_1_PWR_Pin CARD_1_SEL1_Pin CARD_1_SEL2_Pin */
  GPIO_InitStruct.Pin = CARD_6_SPI_SS_Pin|CARD_6_PWR_Pin|CARD_6_SEL1_Pin|CARD_6_SEL2_Pin
                          |DO_LV_CH3_Pin|DO_LV_CH4_Pin|DO_LV_CH6_Pin|SYS_LED_ERROR_Pin
                          |CARD_1_SPI_SS_Pin|CARD_1_PWR_Pin|CARD_1_SEL1_Pin|CARD_1_SEL2_Pin;
  GPIO_InitStruct.Mode = GPIO_MODE_OUTPUT_PP;
  GPIO_InitStruct.Pull = GPIO_NOPULL;
  GPIO_InitStruct.Speed = GPIO_SPEED_FREQ_LOW;
  HAL_GPIO_Init(GPIOF, &GPIO_InitStruct);

  /*Configure GPIO pins : MIL_SWITCH_Pin CARD_5_ID1_Pin CARD_5_ID2_Pin CARD_5_ID3_Pin
                           CARD_3_ID1_Pin CARD_3_ID2_Pin */
  GPIO_InitStruct.Pin = MIL_SWITCH_Pin|CARD_5_ID1_Pin|CARD_5_ID2_Pin|CARD_5_ID3_Pin
                          |CARD_3_ID1_Pin|CARD_3_ID2_Pin;
  GPIO_InitStruct.Mode = GPIO_MODE_INPUT;
  GPIO_InitStruct.Pull = GPIO_NOPULL;
  HAL_GPIO_Init(GPIOA, &GPIO_InitStruct);

  /*Configure GPIO pins : RELAY_5_Pin ADM_CLTR_Pin CARD_3_SEL2_Pin */
  GPIO_InitStruct.Pin = RELAY_5_Pin|ADM_CLTR_Pin|CARD_3_SEL2_Pin;
  GPIO_InitStruct.Mode = GPIO_MODE_OUTPUT_PP;
  GPIO_InitStruct.Pull = GPIO_NOPULL;
  GPIO_InitStruct.Speed = GPIO_SPEED_FREQ_LOW;
  HAL_GPIO_Init(GPIOA, &GPIO_InitStruct);

  /*Configure GPIO pins : CARD_5_PWR_Pin CARD_5_SPI_SS_Pin SYS_LED_STATUS_Pin RELAY_1_Pin
                           RELAY_2_Pin CARD_8_PWR_Pin CARD_8_SEL1_Pin CARD_8_SEL2_Pin
                           CARD_8_SPI_SS_Pin */
  GPIO_InitStruct.Pin = CARD_5_PWR_Pin|CARD_5_SPI_SS_Pin|SYS_LED_STATUS_Pin|RELAY_1_Pin
                          |RELAY_2_Pin|CARD_8_PWR_Pin|CARD_8_SEL1_Pin|CARD_8_SEL2_Pin
                          |CARD_8_SPI_SS_Pin;
  GPIO_InitStruct.Mode = GPIO_MODE_OUTPUT_PP;
  GPIO_InitStruct.Pull = GPIO_NOPULL;
  GPIO_InitStruct.Speed = GPIO_SPEED_FREQ_LOW;
  HAL_GPIO_Init(GPIOB, &GPIO_InitStruct);

  /*Configure GPIO pins : CARD_1_ID1_Pin CARD_1_ID2_Pin CARD_2_ID1_Pin CARD_2_ID2_Pin
                           CARD_2_ID3_Pin RESERVE_PG8_Pin CARD_3_ID3_Pin RESERVE_PG11_Pin
                           RESERVE_PG12_Pin RESERVE_PG13_Pin RESERVE_PG14_Pin RESERVE_PG15_Pin */
  GPIO_InitStruct.Pin = CARD_1_ID1_Pin|CARD_1_ID2_Pin|CARD_2_ID1_Pin|CARD_2_ID2_Pin
                          |CARD_2_ID3_Pin|RESERVE_PG8_Pin|CARD_3_ID3_Pin|RESERVE_PG11_Pin
                          |RESERVE_PG12_Pin|RESERVE_PG13_Pin|RESERVE_PG14_Pin|RESERVE_PG15_Pin;
  GPIO_InitStruct.Mode = GPIO_MODE_INPUT;
  GPIO_InitStruct.Pull = GPIO_NOPULL;
  HAL_GPIO_Init(GPIOG, &GPIO_InitStruct);

  /*Configure GPIO pins : ADM_3_CLTR_Pin CARD_2_SPI_SS_Pin CARD_3_PWR_Pin */
  GPIO_InitStruct.Pin = ADM_3_CLTR_Pin|CARD_2_SPI_SS_Pin|CARD_3_PWR_Pin;
  GPIO_InitStruct.Mode = GPIO_MODE_OUTPUT_PP;
  GPIO_InitStruct.Pull = GPIO_NOPULL;
  GPIO_InitStruct.Speed = GPIO_SPEED_FREQ_LOW;
  HAL_GPIO_Init(GPIOD, &GPIO_InitStruct);

  /*Configure GPIO pins : RESERVE_PD11_Pin RESERVE_PD12_Pin RESERVE_PD13_Pin RESERVE_PD14_Pin */
  GPIO_InitStruct.Pin = RESERVE_PD11_Pin|RESERVE_PD12_Pin|RESERVE_PD13_Pin|RESERVE_PD14_Pin;
  GPIO_InitStruct.Mode = GPIO_MODE_INPUT;
  GPIO_InitStruct.Pull = GPIO_NOPULL;
  HAL_GPIO_Init(GPIOD, &GPIO_InitStruct);

  /*Configure GPIO pins : CARD_2_PWR_Pin CARD_2_SEL1_Pin CARD_2_SEL2_Pin CARD_3_SEL1_Pin */
  GPIO_InitStruct.Pin = CARD_2_PWR_Pin|CARD_2_SEL1_Pin|CARD_2_SEL2_Pin|CARD_3_SEL1_Pin;
  GPIO_InitStruct.Mode = GPIO_MODE_OUTPUT_PP;
  GPIO_InitStruct.Pull = GPIO_NOPULL;
  GPIO_InitStruct.Speed = GPIO_SPEED_FREQ_LOW;
  HAL_GPIO_Init(GPIOG, &GPIO_InitStruct);

}

/* USER CODE BEGIN 4 */

void ReadSlotInfo(void)
{

	//SLOT 1
	SlotCode[1] = 0;//Slot1Code = 0;
	if(HAL_GPIO_ReadPin(GPIOE, GPIO_PIN_5))  // Mux1Code_bit3	PE5
	{
		SlotCode[1] |= 0x08;
	}
	if(HAL_GPIO_ReadPin(GPIOE, GPIO_PIN_4))  // Mux1Code_bit2	PE4
	{
		SlotCode[1] |= 0x04;
	}
	if(HAL_GPIO_ReadPin(GPIOE, GPIO_PIN_3))  // Mux1Code_bit1	PE3
	{
		SlotCode[1] |= 0x02;
	}
	if(HAL_GPIO_ReadPin(GPIOE, GPIO_PIN_2))  // Mux1Code_bit0	PE2
	{
		SlotCode[1] |= 0x01;
	}

	//SLOT 2
	SlotCode[2] = 0;//Slot2Code = 0;
	if(HAL_GPIO_ReadPin(GPIOF, GPIO_PIN_3))  // Mux2Code_bit3	PF3
	{
		SlotCode[2] |= 0x08;
	}
	if(HAL_GPIO_ReadPin(GPIOF, GPIO_PIN_2))  // Mux2Code_bit2	PF2
	{
		SlotCode[2] |= 0x04;
	}
	if(HAL_GPIO_ReadPin(GPIOF, GPIO_PIN_1))  // Mux2Code_bit1	PF1
	{
		SlotCode[2] |= 0x02;
	}
	if(HAL_GPIO_ReadPin(GPIOF, GPIO_PIN_0))  // Mux2Code_bit0	PF0
	{
		SlotCode[2] |= 0x01;
	}

	//SLOT 3
	SlotCode[3] = 0;//Slot3Code = 0;
	if(HAL_GPIO_ReadPin(GPIOA, GPIO_PIN_7))  // Mux3Code_bit3	PA7
	{
		SlotCode[3] |= 0x08;
	}
	if(HAL_GPIO_ReadPin(GPIOA, GPIO_PIN_6))  // Mux3Code_bit2	PA6
	{
		SlotCode[3] |= 0x04;
	}
	if(HAL_GPIO_ReadPin(GPIOA, GPIO_PIN_5))  // Mux3Code_bit1	PA5
	{
		SlotCode[3] |= 0x02;
	}
	if(HAL_GPIO_ReadPin(GPIOA, GPIO_PIN_4))  // Mux3Code_bit0	PA4
	{
		SlotCode[3] |= 0x01;
	}

	//SLOT 4
	SlotCode[4] = 0;//Slot4Code = 0;
	if(HAL_GPIO_ReadPin(GPIOA, GPIO_PIN_7))  // Mux4Code_bit3	PE8
	{
		SlotCode[4] |= 0x08;
	}
	if(HAL_GPIO_ReadPin(GPIOA, GPIO_PIN_7))  // Mux4Code_bit2	PE7
	{
		SlotCode[4] |= 0x04;
	}
	if(HAL_GPIO_ReadPin(GPIOG, GPIO_PIN_1))  // Mux4Code_bit1	PG1
	{
		SlotCode[4] |= 0x02;
	}
	if(HAL_GPIO_ReadPin(GPIOG, GPIO_PIN_0))  // Mux4Code_bit0	PG0
	{
		SlotCode[4] |= 0x01;
	}

	//SLOT 5
	SlotCode[5] = 0;//Slot5Code = 0;
	if(HAL_GPIO_ReadPin(GPIOG, GPIO_PIN_7))  // Mux5Code_bit3	PG8
	{
		SlotCode[5] |= 0x08;
	}
	if(HAL_GPIO_ReadPin(GPIOG, GPIO_PIN_7))  // Mux5Code_bit2	PG7
	{
		SlotCode[5] |= 0x04;
	}
	if(HAL_GPIO_ReadPin(GPIOG, GPIO_PIN_6))  // Mux5Code_bit1	PG6
	{
		SlotCode[5] |= 0x02;
	}
	if(HAL_GPIO_ReadPin(GPIOG, GPIO_PIN_5))  // Mux5Code_bit0	PG5
	{
		SlotCode[5] |= 0x01;
	}

	//SLOT 6
	SlotCode[6] = 0;//Slot6Code = 0;
	if(HAL_GPIO_ReadPin(GPIOA, GPIO_PIN_12))  // Mux6Code_bit3	PA12
	{
		SlotCode[6] |= 0x08;
	}
	if(HAL_GPIO_ReadPin(GPIOA, GPIO_PIN_11))  // Mux6Code_bit2	PA11
	{
		SlotCode[6] |= 0x04;
	}
	if(HAL_GPIO_ReadPin(GPIOA, GPIO_PIN_10))  // Mux6Code_bit1	PA10
	{
		SlotCode[6] |= 0x02;
	}
	if(HAL_GPIO_ReadPin(GPIOA, GPIO_PIN_9))  // Mux6Code_bit0	PA9
	{
		SlotCode[6] |= 0x01;
	}

	//SLOT 7
	SlotCode[7] = 0;//Slot7Code = 0;
	if(HAL_GPIO_ReadPin(GPIOG, GPIO_PIN_14))  // Mux7Code_bit3	PG14
	{
		SlotCode[7] |= 0x08;
	}
	if(HAL_GPIO_ReadPin(GPIOG, GPIO_PIN_13))  // Mux7Code_bit2	PG13
	{
		SlotCode[7] |= 0x04;
	}
	if(HAL_GPIO_ReadPin(GPIOG, GPIO_PIN_12))  // Mux7Code_bit1	PG12
	{
		SlotCode[7] |= 0x02;
	}
	if(HAL_GPIO_ReadPin(GPIOG, GPIO_PIN_11))  // Mux7Code_bit0	PG10
	{
		SlotCode[7] |= 0x01;
	}

	//SLOT 8
	SlotCode[8] = 0;//Slot8Code = 0;
	if(HAL_GPIO_ReadPin(GPIOB, GPIO_PIN_4))  // Mux8Code_bit3	PB4
	{
		SlotCode[8] |= 0x08;
	}
	if(HAL_GPIO_ReadPin(GPIOB, GPIO_PIN_5))  // Mux8Code_bit2	PB5
	{
		SlotCode[8] |= 0x04;
	}
	if(HAL_GPIO_ReadPin(GPIOB, GPIO_PIN_6))  // Mux8Code_bit1	PB6
	{
		SlotCode[8] |= 0x02;
	}
	if(HAL_GPIO_ReadPin(GPIOB, GPIO_PIN_7))  // Mux8Code_bit0	PB7
	{
		SlotCode[8] |= 0x01;
	}

}

void ProcessCommandCommands(void)
{
	switch(HoldingRegister_t.ModeCommand_t.CommonCommand)
	{
		case Sample_pump:
		{
			PumpOperation(0x01);
			break;
		}
		case Clean_pump:
		{
			PumpOperation(0x02);
			break;
		}
		case Measure_sample:
		{
			break;
		}
	}
}

void IOCalculation(uint16_t channel)
{
	switch (channel)
	{
		case AO1:
		{
			break;
		}
	}
}

/*
 * 	LinearEqCalc - Straight line equation. For given two points (x1, y1) and (x2, y2) this function
 * 		calculates and returns y for given x. This is extensively used throughout the project for
 * 		calculation tasks - such as - electronic/Transmitter calibration, sensor calibration or any
 * 		linear relationship.
 * 		Note: convert to macro, if type-less variables are required in future. (Now for float type)
 * 	Parameters -
 * 		float		x		given x value - for which y will be computed
 * 		float		x1		x1 of point (x1, y1)
 * 		float		x2		x2 of point (x2, y2)
 * 		float		y1		y1 of point (x1, y1)
 * 		float		y2		y2 of point (x2, y2)
 * 	Returns -
 * 		float				y computed for given x
 */
float LinearEqCalc(float x, float x1, float x2, float y1, float y2)
{
	return (y1 +  (x - x1) * (y2 - y1) / (x2 - x1));	// equation of straight line for given 2 points. Ref - your school math's textbook!

}
/* USER CODE END 4 */

void Error_Handler(void)
{
}

/************************ (C) COPYRIGHT STMicroelectronics *****END OF FILE****/
